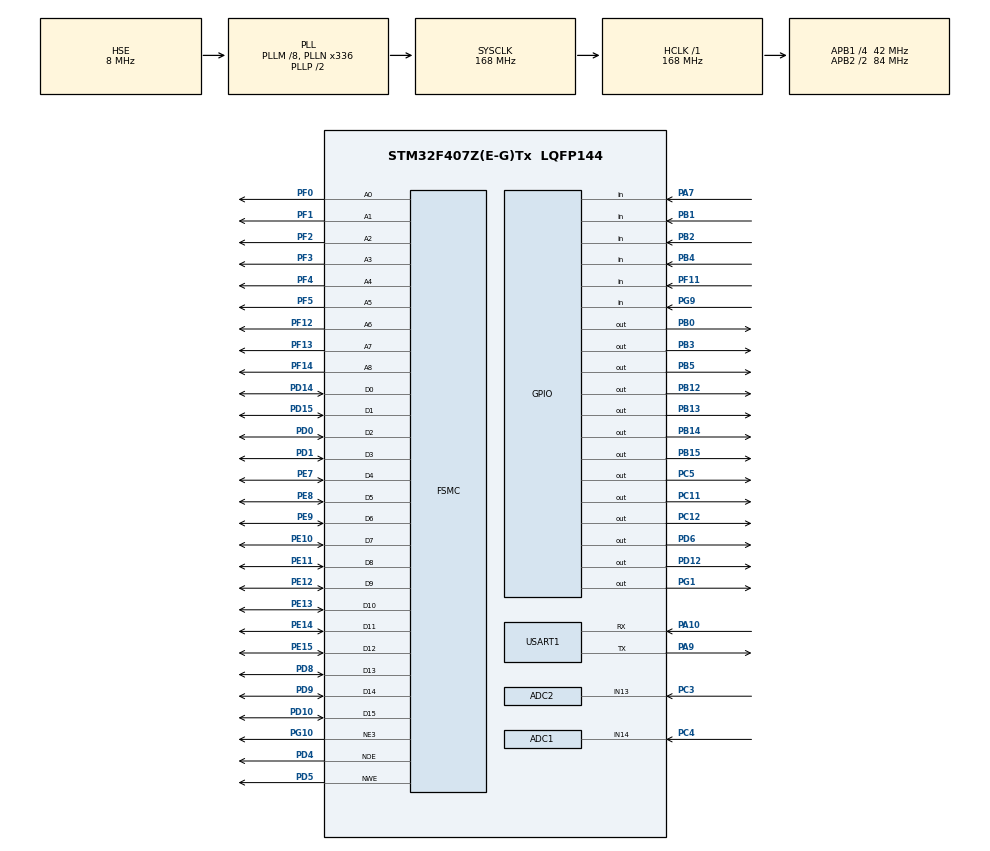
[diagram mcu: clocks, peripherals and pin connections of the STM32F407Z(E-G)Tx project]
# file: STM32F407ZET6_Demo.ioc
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ADC1.Channel-1\#ChannelRegularConversion=ADC_CHANNEL_14
ADC1.ContinuousConvMode=DISABLE
ADC1.NbrOfConversion=1
ADC1.NbrOfConversionFlag=1
ADC1.Rank-1\#ChannelRegularConversion=1
ADC1.SamplingTime-1\#ChannelRegularConversion=ADC_SAMPLETIME_3CYCLES
ADC1.master=1
ADC2.Channel-2\#ChannelRegularConversion=ADC_CHANNEL_13
ADC2.ContinuousConvMode=ENABLE
ADC2.NbrOfConversionFlag=1
ADC2.Rank-2\#ChannelRegularConversion=1
ADC2.SamplingTime-2\#ChannelRegularConversion=ADC_SAMPLETIME_3CYCLES
FSMC.AddressSetupTime1=15
FSMC.BusTurnAroundDuration1=0
FSMC.DataSetupTime1=15
FSMC.ExtendedAddressSetupTime1=15
FSMC.ExtendedBusTurnAroundDuration1=0
FSMC.ExtendedDataSetupTime1=15
FSMC.ExtendedMode1=FSMC_EXTENDED_MODE_ENABLE
FSMC.WriteOperation1=FSMC_WRITE_OPERATION_ENABLE
Mcu.Family=STM32F4
Mcu.Name=STM32F407Z(E-G)Tx
Mcu.Package=LQFP144
NVIC.PriorityGroup=NVIC_PRIORITYGROUP_4
NVIC.TIM6_DAC_IRQn=true\:0\:0\:false\:false\:true\:true\:true\:true
NVIC.USART1_IRQn=true\:0\:0\:false\:false\:true\:true\:true\:true
PA10.Mode=Asynchronous
PA10.Signal=USART1_RX
PA13.Mode=Serial_Wire
PA13.Signal=SYS_JTMS-SWDIO
PA14.Mode=Serial_Wire
PA14.Signal=SYS_JTCK-SWCLK
PA7.Signal=GPIO_Input
PA9.Mode=Asynchronous
PA9.Signal=USART1_TX
PB0.Signal=GPIO_Output
PB1.Signal=GPIO_Input
PB12.Signal=GPIO_Output
PB13.Signal=GPIO_Output
PB14.Signal=GPIO_Output
PB15.Signal=GPIO_Output
PB2.Signal=GPIO_Input
PB3.Signal=GPIO_Output
PB4.Signal=GPIO_Input
PB5.Signal=GPIO_Output
PC11.Signal=GPIO_Output
PC12.Signal=GPIO_Output
PC3.Signal=ADCx_IN13
PC4.Signal=ADCx_IN14
PC5.Signal=GPIO_Output
PD0.Signal=FSMC_D2_DA2
PD1.Signal=FSMC_D3_DA3
PD10.Signal=FSMC_D15_DA15
PD12.GPIO_PuPd=GPIO_PULLUP
PD12.PinState=GPIO_PIN_SET
PD12.Signal=GPIO_Output
PD14.Signal=FSMC_D0_DA0
PD15.Signal=FSMC_D1_DA1
PD4.Signal=FSMC_NOE
PD5.Signal=FSMC_NWE
PD6.GPIO_PuPd=GPIO_PULLUP
PD6.PinState=GPIO_PIN_SET
PD6.Signal=GPIO_Output
PD8.Signal=FSMC_D13_DA13
PD9.Signal=FSMC_D14_DA14
PE10.Signal=FSMC_D7_DA7
PE11.Signal=FSMC_D8_DA8
PE12.Signal=FSMC_D9_DA9
PE13.Signal=FSMC_D10_DA10
PE14.Signal=FSMC_D11_DA11
PE15.Signal=FSMC_D12_DA12
PE7.Signal=FSMC_D4_DA4
PE8.Signal=FSMC_D5_DA5
PE9.Signal=FSMC_D6_DA6
PF0.Signal=FSMC_A0
PF1.Signal=FSMC_A1
PF11.Signal=GPIO_Input
PF12.Signal=FSMC_A6
PF13.Signal=FSMC_A7
PF14.Signal=FSMC_A8
PF2.Signal=FSMC_A2
PF3.Signal=FSMC_A3
PF4.Signal=FSMC_A4
PF5.Signal=FSMC_A5
PG1.GPIO_PuPd=GPIO_PULLDOWN
PG1.PinState=GPIO_PIN_RESET
PG1.Signal=GPIO_Output
PG10.Mode=NorPsramChipSelect3_1
PG10.Signal=FSMC_NE3
PG9.GPIO_PuPd=GPIO_PULLUP
PG9.Signal=GPIO_Input
PH0-OSC_IN.Mode=HSE-External-Oscillator
PH0-OSC_IN.Signal=RCC_OSC_IN
PH1-OSC_OUT.Mode=HSE-External-Oscillator
PH1-OSC_OUT.Signal=RCC_OSC_OUT
ProjectManager.HeapSize=0x400
ProjectManager.StackSize=0x800
ProjectManager.TargetToolchain=MDK-ARM V5.32
RCC.48MHZClocksFreq_Value=84000000
RCC.AHBFreq_Value=168000000
RCC.APB1CLKDivider=RCC_HCLK_DIV4
RCC.APB1Freq_Value=42000000
RCC.APB1TimFreq_Value=84000000
RCC.APB2CLKDivider=RCC_HCLK_DIV2
RCC.APB2Freq_Value=84000000
RCC.APB2TimFreq_Value=168000000
RCC.CortexFreq_Value=168000000
RCC.HCLKFreq_Value=168000000
RCC.HSE_VALUE=8000000
RCC.HSI_VALUE=16000000
RCC.LSE_VALUE=32768
RCC.PLLM=8
RCC.PLLN=336
RCC.PLLSourceVirtual=RCC_PLLSOURCE_HSE
RCC.SYSCLKFreq_VALUE=168000000
RCC.SYSCLKSource=RCC_SYSCLKSOURCE_PLLCLK
RCC.VCOOutputFreq_Value=336000000
SH.ADCx_IN13.0=ADC2_IN13,IN13
SH.ADCx_IN14.0=ADC1_IN14,IN14
SH.ADCx_IN14.1=ADC2_IN14
SH.FSMC_A0.0=FSMC_A0,9b-a1
SH.FSMC_A1.0=FSMC_A1,9b-a1
SH.FSMC_A2.0=FSMC_A2,9b-a1
SH.FSMC_A3.0=FSMC_A3,9b-a1
SH.FSMC_A4.0=FSMC_A4,9b-a1
SH.FSMC_A5.0=FSMC_A5,9b-a1
SH.FSMC_A6.0=FSMC_A6,9b-a1
SH.FSMC_A7.0=FSMC_A7,9b-a1
SH.FSMC_A8.0=FSMC_A8,9b-a1
SH.FSMC_D0_DA0.0=FSMC_D0,16b-d1
SH.FSMC_D10_DA10.0=FSMC_D10,16b-d1
SH.FSMC_D11_DA11.0=FSMC_D11,16b-d1
SH.FSMC_D12_DA12.0=FSMC_D12,16b-d1
SH.FSMC_D13_DA13.0=FSMC_D13,16b-d1
SH.FSMC_D14_DA14.0=FSMC_D14,16b-d1
SH.FSMC_D15_DA15.0=FSMC_D15,16b-d1
SH.FSMC_D1_DA1.0=FSMC_D1,16b-d1
SH.FSMC_D2_DA2.0=FSMC_D2,16b-d1
SH.FSMC_D3_DA3.0=FSMC_D3,16b-d1
SH.FSMC_D4_DA4.0=FSMC_D4,16b-d1
SH.FSMC_D5_DA5.0=FSMC_D5,16b-d1
SH.FSMC_D6_DA6.0=FSMC_D6,16b-d1
SH.FSMC_D7_DA7.0=FSMC_D7,16b-d1
SH.FSMC_D8_DA8.0=FSMC_D8,16b-d1
SH.FSMC_D9_DA9.0=FSMC_D9,16b-d1
SH.FSMC_NOE.0=FSMC_NOE,Sram1
SH.FSMC_NWE.0=FSMC_NWE,Sram1
TIM6.AutoReloadPreload=TIM_AUTORELOAD_PRELOAD_ENABLE
TIM6.Period=9
TIM6.Prescaler=8399
USART1.VirtualMode=VM_ASYNC
VP_TIM6_VS_ClockSourceINT.Mode=Enable_Timer
board=custom

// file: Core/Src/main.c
/* USER CODE BEGIN Header */
/**
  ******************************************************************************
  * @file           : main.c
  * @brief          : Main program body
  ******************************************************************************
  * @attention
  *
  * Copyright (c) 2023 STMicroelectronics.
  * All rights reserved.
  *
  * This software is licensed under terms that can be found in the LICENSE file
  * in the root directory of this software component.
  * If no LICENSE file comes with this software, it is provided AS-IS.
  *
  ******************************************************************************
  */
/* USER CODE END Header */
#include "main.h"
#include "adc.h"
#include "tim.h"
#include "usart.h"
#include "gpio.h"
#include "fsmc.h"

/* USER CODE BEGIN Includes */
#include "stdio.h"
#include "w5300_conf.h"
#include "tcp_client.h"
#include "tcp_server.h"
#include "udp.h"
#include "dhcp.h"
#include "dns.h"
#include "httputil.h"

#include "g5516.h"
#include "dht11.h"
#include "yl_69.h"
#include "relay.h"
#include "serial_studio.h"
#include "show_lcd.h"

/* USER CODE END Includes */

void SystemClock_Config(void);

int main(void)
{

  /* MCU Configuration--------------------------------------------------------*/

  /* Reset of all peripherals, Initializes the Flash interface and the Systick. */
  HAL_Init();

  /* Configure the system clock */
  SystemClock_Config();

  /* Initialize all configured peripherals */
  MX_GPIO_Init();
  MX_USART1_UART_Init();
  MX_FSMC_Init();
  MX_TIM6_Init();
  MX_ADC1_Init();
  MX_ADC2_Init();
  /* USER CODE BEGIN 2 */

LCD_Init();   //LCD init

reset_w5300();  //Reset W5300

set_w5300_mac();   //Configure MAC
set_w5300_netinfo();  //Configure IP GM SN
sysinit();           //Configure socket cache
while(DHT11_Init())   //DHt11 init
printf("\r\n DHT11 Error!");

  while (1)
  {
	Touch_Test(); //Screen display, screen touch control

  }

  /* USER CODE END 3 */
}

void SystemClock_Config(void)
{
  RCC_OscInitTypeDef RCC_OscInitStruct = {0};
  RCC_ClkInitTypeDef RCC_ClkInitStruct = {0};

  /** Configure the main internal regulator output voltage
  */
  __HAL_RCC_PWR_CLK_ENABLE();
  __HAL_PWR_VOLTAGESCALING_CONFIG(PWR_REGULATOR_VOLTAGE_SCALE1);

  /** Initializes the RCC Oscillators according to the specified parameters
  * in the RCC_OscInitTypeDef structure.
  */
  RCC_OscInitStruct.OscillatorType = RCC_OSCILLATORTYPE_HSE;
  RCC_OscInitStruct.HSEState = RCC_HSE_ON;
  RCC_OscInitStruct.PLL.PLLState = RCC_PLL_ON;
  RCC_OscInitStruct.PLL.PLLSource = RCC_PLLSOURCE_HSE;
  RCC_OscInitStruct.PLL.PLLM = 8;
  RCC_OscInitStruct.PLL.PLLN = 336;
  RCC_OscInitStruct.PLL.PLLP = RCC_PLLP_DIV2;
  RCC_OscInitStruct.PLL.PLLQ = 4;
  if (HAL_RCC_OscConfig(&RCC_OscInitStruct) != HAL_OK)
  {
    Error_Handler();
  }

  /** Initializes the CPU, AHB and APB buses clocks
  */
  RCC_ClkInitStruct.ClockType = RCC_CLOCKTYPE_HCLK|RCC_CLOCKTYPE_SYSCLK
                              |RCC_CLOCKTYPE_PCLK1|RCC_CLOCKTYPE_PCLK2;
  RCC_ClkInitStruct.SYSCLKSource = RCC_SYSCLKSOURCE_PLLCLK;
  RCC_ClkInitStruct.AHBCLKDivider = RCC_SYSCLK_DIV1;
  RCC_ClkInitStruct.APB1CLKDivider = RCC_HCLK_DIV4;
  RCC_ClkInitStruct.APB2CLKDivider = RCC_HCLK_DIV2;

  if (HAL_RCC_ClockConfig(&RCC_ClkInitStruct, FLASH_LATENCY_5) != HAL_OK)
  {
    Error_Handler();
  }
}

void Error_Handler(void)
{
  __disable_irq();
  while (1)
  {
  }
}
